/*---------GLOBAL DEFINITIONS-----------*/
LIN_description_file;
LIN_protocol_version = "2.2";
LIN_language_version = "2.2";
LIN_speed = 19.2 kbps;
/* ----------NODE DEFINITIONS---------- */
Nodes {
   Master:
      EVNT, /* Master node name */
      5 ms, /* Time base */
      0.1 ms; /* Jitter */
   Slaves:
      FR_SLLR,
      FR_SLUD,
      FR_CLLR,
      FR_CLUD;
}
/* ----------SIGNAL DEFINITIONS---------- */
Signals {
   /* Signal_name : Size, Init, Publisher, Subscriber(s) */
   EVNT_ADDr : 7, 0x11, EVNT, FR_SLLR,FR_SLUD,FR_CLLR,FR_CLUD;
   EVNT_Broad : 1, 0x00, EVNT, FR_SLLR,FR_SLUD,FR_CLLR,FR_CLUD;
   EVNT_SPEED : 4, 0x00, EVNT, FR_SLLR,FR_SLUD,FR_CLLR,FR_CLUD;
   EVNT_CMD : 8, 0x55, EVNT, FR_SLLR,FR_SLUD,FR_CLLR,FR_CLUD;
   EVNT_Front_Side_LH_LeftRight_TargetPosition: 11, 0x00, EVNT, FR_SLLR;
   EVNT_Front_Side_LH_UpDown_TargetPosition: 11, 0x00, EVNT, FR_SLUD;
   EVNT_Front_Center_LH_LeftRight_TargetPosition: 11, 0x00, EVNT, FR_CLLR;
   EVNT_Front_Center_LH_UpDown_TargetPosition: 11, 0x00, EVNT, FR_CLUD;
   FR_SLLR_SPEED : 4, 0x00, FR_SLLR, EVNT;
   FR_SLLR_OpDone : 1, 0x00, FR_SLLR, EVNT;
   FR_SLLR_STATE : 1, 0x00, FR_SLLR, EVNT;
   FR_SLLR_ActuatorState : 11, 0x00, FR_SLLR, EVNT;
   FR_SLLR_VddReset : 1, 0x00, FR_SLLR, EVNT;
   FR_SLLR_Steploss : 1, 0x00, FR_SLLR, EVNT;
   FR_SLLR_EIDef : 1, 0x00, FR_SLLR, EVNT;
   FR_SLLR_TSD : 1, 0x00, FR_SLLR, EVNT;
   FR_SLLR_TW : 1, 0x00, FR_SLLR, EVNT;
   FR_SLLR_Tinfo : 2, 0x00, FR_SLLR, EVNT;
   FR_SLLR_Sensor : 1, 0x00, FR_SLLR, EVNT;
   FR_SLLR_OV : 1, 0x00, FR_SLLR, EVNT;
   FR_SLLR_UV : 1, 0x00, FR_SLLR, EVNT;
   FR_SLLR_OPEN2 : 1, 0x00, FR_SLLR, EVNT;
   FR_SLLR_OPEN1 : 1, 0x00, FR_SLLR, EVNT;
   FR_SLLR_OVC2 : 1, 0x00, FR_SLLR, EVNT;
   FR_SLLR_OVC1 : 1, 0x00, FR_SLLR, EVNT;
   FR_CLLR_SPEED : 4, 0x00, FR_CLLR, EVNT;
   FR_CLLR_OpDone : 1, 0x00, FR_CLLR, EVNT;
   FR_CLLR_STATE : 1, 0x00, FR_CLLR, EVNT;
   FR_CLLR_ActuatorState : 11, 0x00, FR_CLLR, EVNT;
   FR_CLLR_VddReset : 1, 0x00, FR_CLLR, EVNT;
   FR_CLLR_Steploss : 1, 0x00, FR_CLLR, EVNT;
   FR_CLLR_EIDef : 1, 0x00, FR_CLLR, EVNT;
   FR_CLLR_TSD : 1, 0x00, FR_CLLR, EVNT;
   FR_CLLR_TW : 1, 0x00, FR_CLLR, EVNT;
   FR_CLLR_Tinfo : 2, 0x00, FR_CLLR, EVNT;
   FR_CLLR_Sensor : 1, 0x00, FR_CLLR, EVNT;
   FR_CLLR_OV : 1, 0x00, FR_CLLR, EVNT;
   FR_CLLR_UV : 1, 0x00, FR_CLLR, EVNT;
   FR_CLLR_OPEN2 : 1, 0x00, FR_CLLR, EVNT;
   FR_CLLR_OPEN1 : 1, 0x00, FR_CLLR, EVNT;
   FR_CLLR_OVC2 : 1, 0x00, FR_CLLR, EVNT;
   FR_CLLR_OVC1 : 1, 0x00, FR_CLLR, EVNT;
   FR_SLUD_SPEED : 4, 0x00, FR_SLUD, EVNT;
   FR_SLUD_OpDone : 1, 0x00, FR_SLUD, EVNT;
   FR_SLUD_STATE : 1, 0x00, FR_SLUD, EVNT;
   FR_SLUD_ActuatorState : 11, 0x00, FR_SLUD, EVNT;
   FR_SLUD_VddReset : 1, 0x00, FR_SLUD, EVNT;
   FR_SLUD_Steploss : 1, 0x00, FR_SLUD, EVNT;
   FR_SLUD_EIDef : 1, 0x00, FR_SLUD, EVNT;
   FR_SLUD_TSD : 1, 0x00, FR_SLUD, EVNT;
   FR_SLUD_TW : 1, 0x00, FR_SLUD, EVNT;
   FR_SLUD_Tinfo : 2, 0x00, FR_SLUD, EVNT;
   FR_SLUD_Sensor : 1, 0x00, FR_SLUD, EVNT;
   FR_SLUD_OV : 1, 0x00, FR_SLUD, EVNT;
   FR_SLUD_UV : 1, 0x00, FR_SLUD, EVNT;
   FR_SLUD_OPEN2 : 1, 0x00, FR_SLUD, EVNT;
   FR_SLUD_OPEN1 : 1, 0x00, FR_SLUD, EVNT;
   FR_SLUD_OVC2 : 1, 0x00, FR_SLUD, EVNT;
   FR_SLUD_OVC1 : 1, 0x00, FR_SLUD, EVNT;
   FR_CLUD_SPEED : 4, 0x00, FR_CLUD, EVNT;
   FR_CLUD_OpDone : 1, 0x00, FR_CLUD, EVNT;
   FR_CLUD_STATE : 1, 0x00, FR_CLUD, EVNT;
   FR_CLUD_ActuatorState : 11, 0x00, FR_CLUD, EVNT;
   FR_CLUD_VddReset : 1, 0x00, FR_CLUD, EVNT;
   FR_CLUD_Steploss : 1, 0x00, FR_CLUD, EVNT;
   FR_CLUD_EIDef : 1, 0x00, FR_CLUD, EVNT;
   FR_CLUD_TSD : 1, 0x00, FR_CLUD, EVNT;
   FR_CLUD_TW : 1, 0x00, FR_CLUD, EVNT;
   FR_CLUD_Tinfo : 2, 0x00, FR_CLUD, EVNT;
   FR_CLUD_Sensor : 1, 0x00, FR_CLUD, EVNT;
   FR_CLUD_OV : 1, 0x00, FR_CLUD, EVNT;
   FR_CLUD_UV : 1, 0x00, FR_CLUD, EVNT;
   FR_CLUD_OPEN2 : 1, 0x00, FR_CLUD, EVNT;
   FR_CLUD_OPEN1 : 1, 0x00, FR_CLUD, EVNT;
   FR_CLUD_OVC2 : 1, 0x00, FR_CLUD, EVNT;
   FR_CLUD_OVC1 : 1, 0x00, FR_CLUD, EVNT;
}
/* ----------DIAGNOSTIC SIGNAL DEFINITIONS---------- */
Diagnostic_signals {
   /* MasterReq Reserved Signals */
   MasterReqB0 : 8, 0;
   MasterReqB1 : 8, 0;
   MasterReqB2 : 8, 0;
   MasterReqB3 : 8, 0;
   MasterReqB4 : 8, 0;
   MasterReqB5 : 8, 0;
   MasterReqB6 : 8, 0;
   MasterReqB7 : 8, 0;
   /* SlaveResp Reserved Signals */
   SlaveRespB0 : 8, 0;
   SlaveRespB1 : 8, 0;
   SlaveRespB2 : 8, 0;
   SlaveRespB3 : 8, 0;
   SlaveRespB4 : 8, 0;
   SlaveRespB5 : 8, 0;
   SlaveRespB6 : 8, 0;
   SlaveRespB7 : 8, 0;
}
/* ----------UNCONDITIONAL FRAME DEFINITIONS---------- */
Frames {
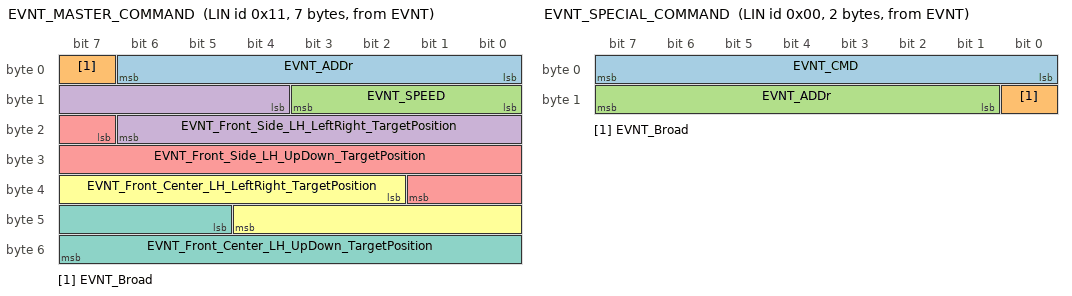
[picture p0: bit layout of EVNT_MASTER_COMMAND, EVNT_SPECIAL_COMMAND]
   EVNT_MASTER_COMMAND : 0x11, EVNT , 7 {
      EVNT_ADDr , 0;
      EVNT_Broad , 7;
      EVNT_SPEED , 8;
      EVNT_Front_Side_LH_LeftRight_TargetPosition, 12;
      EVNT_Front_Side_LH_UpDown_TargetPosition, 23;
      EVNT_Front_Center_LH_LeftRight_TargetPosition, 34;
      EVNT_Front_Center_LH_UpDown_TargetPosition, 45;
   }
   FR_SLLR_STATUS : 0x12, FR_SLLR , 4 {
      FR_SLLR_SPEED , 0;
      FR_SLLR_ActuatorState, 5;
      FR_SLLR_OpDone , 16;
      FR_SLLR_VddReset , 17;
      FR_SLLR_Steploss , 18;
      FR_SLLR_EIDef , 19;
      FR_SLLR_TSD , 20;
      FR_SLLR_TW , 21;
      FR_SLLR_Tinfo , 22;
      FR_SLLR_STATE , 24;
      FR_SLLR_Sensor , 25;
      FR_SLLR_OV , 26;
      FR_SLLR_UV , 27;
      FR_SLLR_OPEN2 , 28;
      FR_SLLR_OPEN1 , 29;
      FR_SLLR_OVC2 , 30;
      FR_SLLR_OVC1 , 31;
   }
   FR_SLUD_STATUS : 0x13, FR_SLUD , 4 {
      FR_SLUD_SPEED , 0;
      FR_SLUD_ActuatorState, 5;
      FR_SLUD_OpDone , 16;
      FR_SLUD_VddReset , 17;
      FR_SLUD_Steploss , 18;
      FR_SLUD_EIDef , 19;
      FR_SLUD_TSD , 20;
      FR_SLUD_TW , 21;
      FR_SLUD_Tinfo , 22;
      FR_SLUD_STATE , 24;
      FR_SLUD_Sensor , 25;
      FR_SLUD_OV , 26;
      FR_SLUD_UV , 27;
      FR_SLUD_OPEN2 , 28;
      FR_SLUD_OPEN1 , 29;
      FR_SLUD_OVC2 , 30;
      FR_SLUD_OVC1 , 31;
   }
   FR_CLLR_STATUS : 0x14, FR_CLLR , 4 {
      FR_CLLR_SPEED , 0;
      FR_CLLR_ActuatorState, 5;
      FR_CLLR_OpDone , 16;
      FR_CLLR_VddReset , 17;
      FR_CLLR_Steploss , 18;
      FR_CLLR_EIDef , 19;
      FR_CLLR_TSD , 20;
      FR_CLLR_TW , 21;
      FR_CLLR_Tinfo , 22;
      FR_CLLR_STATE , 24;
      FR_CLLR_Sensor , 25;
      FR_CLLR_OV , 26;
      FR_CLLR_UV , 27;
      FR_CLLR_OPEN2 , 28;
      FR_CLLR_OPEN1 , 29;
      FR_CLLR_OVC2 , 30;
      FR_CLLR_OVC1 , 31;
   }
   FR_CLUD_STATUS : 0x15, FR_CLUD , 4 {
      FR_CLUD_SPEED , 0;
      FR_CLUD_ActuatorState, 5;
      FR_CLUD_OpDone , 16;
      FR_CLUD_VddReset , 17;
      FR_CLUD_Steploss , 18;
      FR_CLUD_EIDef , 19;
      FR_CLUD_TSD , 20;
      FR_CLUD_TW , 21;
      FR_CLUD_Tinfo , 22;
      FR_CLUD_STATE , 24;
      FR_CLUD_Sensor , 25;
      FR_CLUD_OV , 26;
      FR_CLUD_UV , 27;
      FR_CLUD_OPEN2 , 28;
      FR_CLUD_OPEN1 , 29;
      FR_CLUD_OVC2 , 30;
      FR_CLUD_OVC1 , 31;
   }
   EVNT_SPECIAL_COMMAND: 0x00, EVNT , 2 {
      EVNT_CMD , 0;
      EVNT_Broad , 8;
      EVNT_ADDr , 9;
   }
}
/* ----------DIAGNOSTIC FRAME DEFINITIONS---------- */
Diagnostic_frames {
   MasterReq : 0x3C {
      MasterReqB0 , 0;
      MasterReqB1 , 8;
      MasterReqB2 , 16;
      MasterReqB3 , 24;
      MasterReqB4 , 32;
      MasterReqB5 , 40;
      MasterReqB6 , 48;
      MasterReqB7 , 56;
   }
   SlaveResp : 0x3D {
      SlaveRespB0 , 0;
      SlaveRespB1 , 8;
      SlaveRespB2 , 16;
      SlaveRespB3 , 24;
      SlaveRespB4 , 32;
      SlaveRespB5 , 40;
      SlaveRespB6 , 48;
      SlaveRespB7 , 56;
   }
}
/* ----------NODE ATTRIBUTE DEFINITIONS---------- */
Node_attributes {
   FR_SLLR {
      LIN_protocol = "2.2"; /* Node protocol version */
      configured_NAD = 0x11; /* configured NAD of node */
      initial_NAD = 0x11; /* initial NAD of node */
      product_id = 0x0115, 0x1100, 0xFF; /* Product id */
      response_error = FR_SLLR_STATE; /* Response error signal */
      P2_min = 50 ms; /* P2_min */
      ST_min = 0 ms; /* ST_min */
      N_As_timeout = 1000 ms; /* N_As_timeout */
      N_Cr_timeout = 1000 ms; /* N_As_timeout */
      configurable_frames {
         EVNT_MASTER_COMMAND;
         FR_SLLR_STATUS;
         EVNT_SPECIAL_COMMAND;
      }
   }
   FR_SLUD {
      LIN_protocol = "2.2"; /* Node protocol version */
      configured_NAD = 0x12; /* configured NAD of node */
      initial_NAD = 0x12; /* initial NAD of node */
      product_id = 0x0115, 0x1100, 0xFF; /* Product id */
      response_error = FR_SLUD_STATE; /* Response error signal */
      P2_min = 50 ms; /* P2_min */
      ST_min = 0 ms; /* ST_min */
      N_As_timeout = 1000 ms; /* N_As_timeout */
      N_Cr_timeout = 1000 ms; /* N_As_timeout */
      configurable_frames {
         EVNT_MASTER_COMMAND;
         FR_SLUD_STATUS;
         EVNT_SPECIAL_COMMAND;
      }
   }
   FR_CLLR {
      LIN_protocol = "2.2"; /* Node protocol version */
      configured_NAD = 0x13; /* configured NAD of node */
      initial_NAD = 0x13; /* initial NAD of node */
      product_id = 0x0115, 0x1100, 0xFF; /* Product id */
      response_error = FR_CLLR_STATE; /* Response error signal */
      P2_min = 50 ms; /* P2_min */
      ST_min = 0 ms; /* ST_min */
      N_As_timeout = 1000 ms; /* N_As_timeout */
      N_Cr_timeout = 1000 ms; /* N_As_timeout */
      configurable_frames {
         EVNT_MASTER_COMMAND;
         FR_CLLR_STATUS;
         EVNT_SPECIAL_COMMAND;
      }
   }
   FR_CLUD {
      LIN_protocol = "2.2"; /* Node protocol version */
      configured_NAD = 0x14; /* configured NAD of node */
      initial_NAD = 0x14; /* initial NAD of node */
      product_id = 0x0115, 0x1100, 0xFF; /* Product id */
      response_error = FR_CLUD_STATE; /* Response error signal */
      P2_min = 50 ms; /* P2_min */
      ST_min = 0 ms; /* ST_min */
      N_As_timeout = 1000 ms; /* N_As_timeout */
      N_Cr_timeout = 1000 ms; /* N_As_timeout */
      configurable_frames {
         EVNT_MASTER_COMMAND;
         FR_CLUD_STATUS;
         EVNT_SPECIAL_COMMAND;
      }
   }
}
/* ----------SCHEDULE TABLE DEFINITIONS---------- */
Schedule_tables {
   SCHEDULER_EVNT_NORMAL_FR_DRV {
      EVNT_MASTER_COMMAND delay 10 ms;
      FR_SLLR_STATUS delay 10 ms;
      FR_SLUD_STATUS delay 10 ms;
      FR_CLLR_STATUS delay 10 ms;
      FR_CLUD_STATUS delay 10 ms;
   }
   SCHEDULER_EVNT_SPECIAL_CMD_FR_DRV {
      EVNT_SPECIAL_COMMAND delay 10 ms;
      EVNT_SPECIAL_COMMAND delay 10 ms;
   }
   Diag_request {
      MasterReq delay 10 ms;
   }
   Diag_response {
      SlaveResp delay 10 ms;
   }
}
/* ----------SIGNAL ENCODDING DEFINITIONS---------- */
Signal_encoding_types {
   ADDr_Sig_Type {
      logical_value,17,"Front_Side_LH_Left/Right_Actuator";
      logical_value,18,"Front_Side_LH_Up/Down_Actuator";
      logical_value,19,"Front_Center_LH_Left_Left/Right_Actuator";
      logical_value,20,"Front_Center_LH_Left_Up/Down_Actuator";
   }
   Broad_Sig_Type {
      logical_value,0,"Broadcast";
      logical_value,1,"Unicast";
   }
   ElDef_Sig_Type {
      logical_value,0,"Normal_state";
      logical_value,1,"Electrical_Defect";
   }
   OPEN1_Sig_Type {
      logical_value,0,"Normal_state";
      logical_value,1,"Motor_Coil_A_Open";
   }
   OPEN2_Sig_Type {
      logical_value,0,"Normal_state";
      logical_value,1,"Motor_Coil_B_Open";
   }
   OVC1_Sig_Type {
      logical_value,0,"Normal_state";
      logical_value,1,"Motor_Coil_A_Short";
   }
   OVC2_Sig_Type {
      logical_value,0,"Normal_state";
      logical_value,1,"Motor_Coil_B_Short";
   }
   OV_Sig_Type {
      logical_value,0,"Normal_state";
      logical_value,1,"Over_Voltage";
   }
   OpDone_Sig_Type {
      logical_value,0,"Moving";
      logical_value,1,"Destination";
   }
   SPECIAL_CMD_Type {
      logical_value,85,"Hard Stop";
   }
   SPEED_Sig_Type {
      logical_value,0,"Level 0 (0 rpm)";
      logical_value,1,"Level 1 (1 rpm)";
      logical_value,2,"Level 2 (2 rpm)";
      logical_value,3,"Level 3 (3 rpm)";
      logical_value,4,"Level 4 (4 rpm)";
      logical_value,5,"Level 5 (5 rpm)";
      logical_value,6,"Level 6 (6 rpm)";
      logical_value,7,"Level 7 (7 rpm)";
      logical_value,8,"Level 8 (8 rpm)";
      logical_value,9,"Level 9 (9 rpm)";
      logical_value,10,"Level 10 (10 rpm)";
   }
   STAUTS_Sig_Type {
      logical_value,0,"No_error";
      logical_value,1,"Error";
   }
   Sensor_Sig_Type {
      logical_value,0,"Normal_state";
      logical_value,1,"Sensor_Error";
   }
   Steploss_Sig_Type {
      logical_value,0,"Normal_state";
      logical_value,1,"Steploss";
   }
   TSD_Sig_Type {
      logical_value,0,"Normal_state";
      logical_value,1,"TSD_Thermal Shutdown";
   }
   TW_Sig_Type {
      logical_value,0,"Normal_state";
      logical_value,1,"TW_Thermal Shutdown";
   }
   Tinfo_Sig_Type {
      logical_value,0,"Normal_temperature ";
      logical_value,1,"Low_temperature ";
      logical_value,2,"High_temperature ";
      logical_value,3,"Not_Use";
   }
   UV_Sig_Type {
      logical_value,0,"Normal_state";
      logical_value,1,"Under_Voltage";
   }
   VddReset_Sig_Type {
      logical_value,0,"Normal_state";
      logical_value,1,"Power ON Reset";
   }
}
/* ----------SIGNAL REPRESENTATION DEFINITIONS---------- */
Signal_representation {
   ADDr_Sig_Type:EVNT_ADDr;
   Broad_Sig_Type:EVNT_Broad;
   ElDef_Sig_Type:FR_SLLR_EIDef,FR_CLLR_EIDef,FR_SLUD_EIDef,FR_CLUD_EIDef;
   OPEN1_Sig_Type:FR_SLLR_OPEN1,FR_CLLR_OPEN1,FR_SLUD_OPEN1,FR_CLUD_OPEN1;
   OPEN2_Sig_Type:FR_SLLR_OPEN2,FR_CLLR_OPEN2,FR_SLUD_OPEN2,FR_CLUD_OPEN2;
   OVC1_Sig_Type:FR_SLLR_OVC1,FR_CLLR_OVC1,FR_SLUD_OVC1,FR_CLUD_OVC1;
   OVC2_Sig_Type:FR_SLLR_OVC2,FR_CLLR_OVC2,FR_SLUD_OVC2,FR_CLUD_OVC2;
   OV_Sig_Type:FR_SLLR_OV,FR_CLLR_OV,FR_SLUD_OV,FR_CLUD_OV;
   OpDone_Sig_Type:FR_SLLR_OpDone,FR_CLLR_OpDone,FR_SLUD_OpDone,FR_CLUD_OpDone;
   SPECIAL_CMD_Type:EVNT_CMD;
   SPEED_Sig_Type:EVNT_SPEED,FR_SLLR_SPEED,FR_CLLR_SPEED,FR_SLUD_SPEED,FR_CLUD_SPEED;
   STAUTS_Sig_Type:FR_SLLR_STATE,FR_CLLR_STATE,FR_SLUD_STATE,FR_CLUD_STATE;
   Sensor_Sig_Type:FR_SLLR_Sensor,FR_CLLR_Sensor,FR_SLUD_Sensor,FR_CLUD_Sensor;
   Steploss_Sig_Type:FR_SLLR_Steploss,FR_CLLR_Steploss,FR_SLUD_Steploss,FR_CLUD_Steploss;
   TSD_Sig_Type:FR_SLLR_TSD,FR_CLLR_TSD,FR_SLUD_TSD,FR_CLUD_TSD;
   TW_Sig_Type:FR_SLLR_TW,FR_CLLR_TW,FR_SLUD_TW,FR_CLUD_TW;
   Tinfo_Sig_Type:FR_SLLR_Tinfo,FR_CLLR_Tinfo,FR_SLUD_Tinfo,FR_CLUD_Tinfo;
   UV_Sig_Type:FR_SLLR_UV,FR_CLLR_UV,FR_SLUD_UV,FR_CLUD_UV;
   VddReset_Sig_Type:FR_SLLR_VddReset,FR_CLLR_VddReset,FR_SLUD_VddReset,FR_CLUD_VddReset;
}
